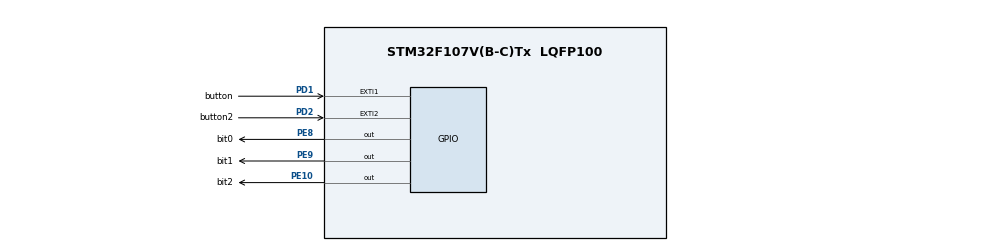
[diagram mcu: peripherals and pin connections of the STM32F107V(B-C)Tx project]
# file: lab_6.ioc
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Mcu.Family=STM32F1
Mcu.Name=STM32F107V(B-C)Tx
Mcu.Package=LQFP100
NVIC.EXTI1_IRQn=true\:0\:0\:false\:false\:true\:true\:true
NVIC.EXTI2_IRQn=true\:0\:0\:false\:false\:true\:true\:true
NVIC.PriorityGroup=NVIC_PRIORITYGROUP_4
OSC_IN.Mode=HSE-External-Oscillator
OSC_IN.Signal=RCC_OSC_IN
OSC_OUT.Mode=HSE-External-Oscillator
OSC_OUT.Signal=RCC_OSC_OUT
PA13.Mode=Serial_Wire
PA13.Signal=SYS_JTMS-SWDIO
PA14.Mode=Serial_Wire
PA14.Signal=SYS_JTCK-SWCLK
PD1.GPIO_Label=button
PD1.Signal=GPXTI1
PD2.GPIO_Label=button2
PD2.Signal=GPXTI2
PE10.GPIO_Label=bit2
PE10.Signal=GPIO_Output
PE8.GPIO_Label=bit0
PE8.Signal=GPIO_Output
PE9.GPIO_Label=bit1
PE9.Signal=GPIO_Output
ProjectManager.HeapSize=0x200
ProjectManager.StackSize=0x400
ProjectManager.TargetToolchain=MDK-ARM V5.32
RCC.USBFreq_Value=10666666.666666666
board=custom

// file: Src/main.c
/* USER CODE BEGIN Header */
/**
  ******************************************************************************
  * @file           : main.c
  * @brief          : Main program body
  ******************************************************************************
  * @attention
  *
  * Copyright (c) 2022 STMicroelectronics.
  * All rights reserved.
  *
  * This software is licensed under terms that can be found in the LICENSE file
  * in the root directory of this software component.
  * If no LICENSE file comes with this software, it is provided AS-IS.
  *
  ******************************************************************************
  */
/* USER CODE END Header */
#include "main.h"

/* USER CODE BEGIN PV */
uint8_t current_number = 0;
/* USER CODE END PV */

void SystemClock_Config(void);
static void MX_GPIO_Init(void);

int main(void)
{

  /* MCU Configuration--------------------------------------------------------*/

  /* Reset of all peripherals, Initializes the Flash interface and the Systick. */
  HAL_Init();

  /* Configure the system clock */
  SystemClock_Config();

  /* Initialize all configured peripherals */
  MX_GPIO_Init();

  /* Infinite loop */
  /* USER CODE BEGIN WHILE */
	GPIO_PinState button_value_current = GPIO_PIN_RESET;
	GPIO_PinState button_value_previous = GPIO_PIN_RESET;

  while (1)
  {
		button_value_previous = button_value_current;
		button_value_current = HAL_GPIO_ReadPin(button_GPIO_Port, button_Pin);

    /* USER CODE END WHILE */

  }
}

void SystemClock_Config(void)
{
  RCC_OscInitTypeDef RCC_OscInitStruct = {0};
  RCC_ClkInitTypeDef RCC_ClkInitStruct = {0};

  /** Initializes the RCC Oscillators according to the specified parameters
  * in the RCC_OscInitTypeDef structure.
  */
  RCC_OscInitStruct.OscillatorType = RCC_OSCILLATORTYPE_HSI;
  RCC_OscInitStruct.HSIState = RCC_HSI_ON;
  RCC_OscInitStruct.HSICalibrationValue = RCC_HSICALIBRATION_DEFAULT;
  RCC_OscInitStruct.PLL.PLLState = RCC_PLL_NONE;
  RCC_OscInitStruct.PLL2.PLL2State = RCC_PLL_NONE;
  if (HAL_RCC_OscConfig(&RCC_OscInitStruct) != HAL_OK)
  {
    Error_Handler();
  }
  /** Initializes the CPU, AHB and APB buses clocks
  */
  RCC_ClkInitStruct.ClockType = RCC_CLOCKTYPE_HCLK|RCC_CLOCKTYPE_SYSCLK
                              |RCC_CLOCKTYPE_PCLK1|RCC_CLOCKTYPE_PCLK2;
  RCC_ClkInitStruct.SYSCLKSource = RCC_SYSCLKSOURCE_HSI;
  RCC_ClkInitStruct.AHBCLKDivider = RCC_SYSCLK_DIV1;
  RCC_ClkInitStruct.APB1CLKDivider = RCC_HCLK_DIV1;
  RCC_ClkInitStruct.APB2CLKDivider = RCC_HCLK_DIV1;

  if (HAL_RCC_ClockConfig(&RCC_ClkInitStruct, FLASH_LATENCY_0) != HAL_OK)
  {
    Error_Handler();
  }
  /** Configure the Systick interrupt time
  */
  __HAL_RCC_PLLI2S_ENABLE();
}

static void MX_GPIO_Init(void)
{
  GPIO_InitTypeDef GPIO_InitStruct = {0};

  /* GPIO Ports Clock Enable */
  __HAL_RCC_GPIOE_CLK_ENABLE();
  __HAL_RCC_GPIOA_CLK_ENABLE();
  __HAL_RCC_GPIOD_CLK_ENABLE();

  /*Configure GPIO pin Output Level */
  HAL_GPIO_WritePin(GPIOE, GPIO_PIN_8|GPIO_PIN_9|GPIO_PIN_10, GPIO_PIN_RESET);

  /*Configure GPIO pins : PE8 PE9 PE10 */
  GPIO_InitStruct.Pin = GPIO_PIN_8|GPIO_PIN_9|GPIO_PIN_10;
  GPIO_InitStruct.Mode = GPIO_MODE_OUTPUT_PP;
  GPIO_InitStruct.Pull = GPIO_NOPULL;
  GPIO_InitStruct.Speed = GPIO_SPEED_FREQ_LOW;
  HAL_GPIO_Init(GPIOE, &GPIO_InitStruct);

  /*Configure GPIO pins : PD1 PD2 */
  GPIO_InitStruct.Pin = GPIO_PIN_1|GPIO_PIN_2;
  GPIO_InitStruct.Mode = GPIO_MODE_IT_RISING;
  GPIO_InitStruct.Pull = GPIO_NOPULL;
  HAL_GPIO_Init(GPIOD, &GPIO_InitStruct);

  /* EXTI interrupt init*/
  HAL_NVIC_SetPriority(EXTI1_IRQn, 0, 0);
  HAL_NVIC_EnableIRQ(EXTI1_IRQn);

  HAL_NVIC_SetPriority(EXTI2_IRQn, 0, 0);
  HAL_NVIC_EnableIRQ(EXTI2_IRQn);

}

/* USER CODE BEGIN 4 */
void Update_Leds(uint8_t current_number){
			GPIO_PinState bit0_value, bit1_value;
		bit0_value = (current_number & (uint8_t)1) ? GPIO_PIN_SET:GPIO_PIN_RESET;
		bit1_value = (current_number & (uint8_t)2) ? GPIO_PIN_SET:GPIO_PIN_RESET; //0b00010
		// Turn on/off LED according to the current number
		//HAL_GPIO_WritePin(bit0_GPIO_Port, bit0_Pin, bit0_value);
		//HAL_GPIO_WritePin(bit1_GPIO_Port, bit1_Pin, bit1_value);
		//bit0_GPIO_Port->ODR = (bit0_value ? bit0_Pin : 0) | (bit1_value ? bit1_Pin : 0);
		//(uint32_t)GPIO_Pin << 16u
		bit0_GPIO_Port->BSRR = (bit0_value ? bit0_Pin : bit0_Pin << 16u) | (bit1_value ? bit1_Pin : bit1_Pin << 16u);
	return;
/* USER CODE END 4 */
}
void Error_Handler(void)
{
  __disable_irq();
  while (1)
  {
  }
}
